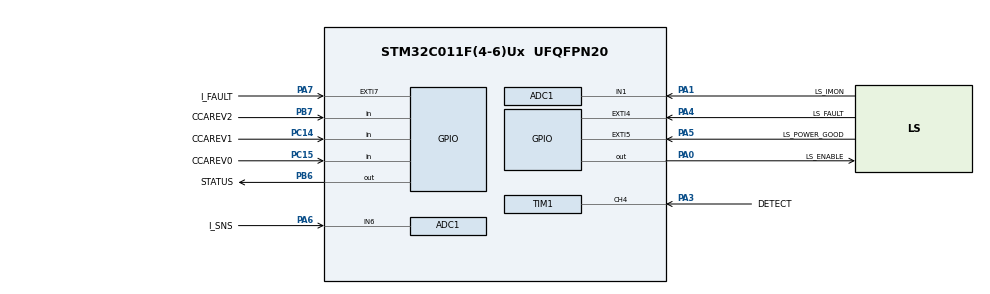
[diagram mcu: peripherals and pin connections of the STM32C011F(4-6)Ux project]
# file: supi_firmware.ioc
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ADC1.AWD2HighThreshold=3165
ADC1.AWD2ITMode=ENABLE
ADC1.AWDChannel-0\#ChannelRegularConversion=ADC_CHANNEL_6
ADC1.Channel-0\#ChannelRegularConversion=ADC_CHANNEL_6
ADC1.ContinuousConvMode=ENABLE
ADC1.DataAlign=ADC_DATAALIGN_RIGHT
ADC1.EnableAnalogWatchDog1=false
ADC1.EnableAnalogWatchDog2=true
ADC1.EnableAnalogWatchDog3=false
ADC1.MonitoredBy-0\#ChannelRegularConversion=ADC_ANALOGWATCHDOG_2
ADC1.NbrOfConversion=1
ADC1.NbrOfConversionFlag=1
ADC1.Overrun=ADC_OVR_DATA_OVERWRITTEN
ADC1.OversamplingMode=DISABLE
ADC1.Rank-0\#ChannelRegularConversion=1
ADC1.SamplingTime-0\#ChannelRegularConversion=ADC_SAMPLINGTIME_COMMON_1
ADC1.SamplingTimeCommon1=ADC_SAMPLETIME_1CYCLE_5
ADC1.SamplingTimeCommon2=ADC_SAMPLETIME_1CYCLE_5
ADC1.SelectedChannel=ADC_CHANNEL_1|ADC_CHANNEL_6
ADC1.WDG2ChannelR1=ADC_CHANNEL_6
ADC1.master=1
Mcu.Family=STM32C0
Mcu.Name=STM32C011F(4-6)Ux
Mcu.Package=UFQFPN20
NVIC.ADC1_IRQn=true\:0\:0\:false\:false\:true\:true\:true\:true
PA0.GPIO_Label=LS_ENABLE
PA0.Signal=GPIO_Output
PA1.GPIO_Label=LS_IMON
PA1.Mode=IN1
PA1.Signal=ADC1_IN1
PA13.Mode=Serial_Wire
PA13.Signal=DEBUG_SWDIO
PA14-BOOT0.Mode=Serial_Wire
PA14-BOOT0.Signal=DEBUG_SWCLK
PA3.GPIO_Label=DETECT
PA3.Signal=S_TIM1_CH4
PA4.GPIO_Label=LS_FAULT
PA4.GPIO_ModeDefaultEXTI=GPIO_MODE_IT_RISING
PA4.Signal=GPXTI4
PA5.GPIO_Label=LS_POWER_GOOD
PA5.Signal=GPXTI5
PA6.GPIO_Label=I_SNS
PA6.Mode=IN6
PA6.Signal=ADC1_IN6
PA7.GPIO_Label=I_FAULT
PA7.Signal=GPXTI7
PB6.GPIO_FM6=SYSCFG_FASTMODEPLUS_PB6
PB6.GPIO_Label=STATUS
PB6.GPIO_Speed=GPIO_SPEED_FREQ_VERY_HIGH
PB6.Signal=GPIO_Output
PB7.GPIO_Label=CCAREV2
PB7.GPIO_PuPd=GPIO_PULLDOWN
PB7.Signal=GPIO_Input
PC14-OSCX_IN\ (PC14).GPIO_Label=CCAREV1
PC14-OSCX_IN\ (PC14).GPIO_PuPd=GPIO_PULLDOWN
PC14-OSCX_IN\ (PC14).Signal=GPIO_Input
PC15-OSCX_OUT\ (PC15).GPIO_Label=CCAREV0
PC15-OSCX_OUT\ (PC15).GPIO_PuPd=GPIO_PULLDOWN
PC15-OSCX_OUT\ (PC15).Signal=GPIO_Input
ProjectManager.HeapSize=0x200
ProjectManager.StackSize=0x400
ProjectManager.TargetToolchain=MDK-ARM V5.32
RCC.ADCFreq_Value=48000000
RCC.AHBFreq_Value=48000000
RCC.CortexFreq_Value=48000000
RCC.EXTERNAL_CLOCK_VALUE=12288000
RCC.HCLKFreq_Value=48000000
RCC.HSE_VALUE=8000000
RCC.HSISYSCLKDivider=RCC_HSI_DIV1
RCC.HSI_VALUE=48000000
RCC.LSE_VALUE=32768
RCC.SYSCLKFreq_VALUE=48000000
SH.S_TIM1_CH4.0=TIM1_CH4,Input_Capture4_from_TI4
TIM1.Channel-Input_Capture4_from_TI4=TIM_CHANNEL_4
TIM1.ICFilter_CH4=3
TIM1.ICPolarity_CH4=TIM_INPUTCHANNELPOLARITY_FALLING
TIM1.Prescaler=48
TIM14.Channel=TIM_CHANNEL_1
TIM14.Prescaler=48
VP_TIM14_VS_ClockSourceINT.Mode=Enable_Timer
VP_TIM14_VS_OPM.Mode=OPM_bit
VP_TIM14_VS_no_output1.Mode=Output Compare1 No Output
VP_TIM1_VS_OPM.Mode=OPM_bit
board=custom

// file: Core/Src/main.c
/* USER CODE BEGIN Header */
/**
  ******************************************************************************
  * @file           : main.c
  * @brief          : Main program body
  ******************************************************************************
  * @attention
  *
  * Copyright (c) 2023 STMicroelectronics.
  * All rights reserved.
  *
  * This software is licensed under terms that can be found in the LICENSE file
  * in the root directory of this software component.
  * If no LICENSE file comes with this software, it is provided AS-IS.
  *
  ******************************************************************************
  */
/* USER CODE END Header */
#include "main.h"

/* USER CODE BEGIN Includes */
#include "supi.h"
/* USER CODE END Includes */

ADC_HandleTypeDef hadc1;

TIM_HandleTypeDef htim1;
TIM_HandleTypeDef htim14;

void SystemClock_Config(void);
static void MX_GPIO_Init(void);
static void MX_ADC1_Init(void);
static void MX_TIM1_Init(void);
static void MX_TIM14_Init(void);

int main(void)
{

  /* MCU Configuration--------------------------------------------------------*/

  /* Reset of all peripherals, Initializes the Flash interface and the Systick. */
  HAL_Init();

  /* Configure the system clock */
  SystemClock_Config();

  /* Initialize all configured peripherals */
  MX_GPIO_Init();
  MX_ADC1_Init();
  MX_TIM1_Init();
  MX_TIM14_Init();
  /* USER CODE BEGIN 2 */
    HAL_ADCEx_Calibration_Start(&hadc1);
    supi_initialize();
  /* USER CODE END 2 */

  /* Infinite loop */
  while (1)
  {

  }
}

void SystemClock_Config(void)
{
  RCC_OscInitTypeDef RCC_OscInitStruct = {0};
  RCC_ClkInitTypeDef RCC_ClkInitStruct = {0};

  /** Initializes the RCC Oscillators according to the specified parameters
  * in the RCC_OscInitTypeDef structure.
  */
  RCC_OscInitStruct.OscillatorType = RCC_OSCILLATORTYPE_HSI;
  RCC_OscInitStruct.HSIState = RCC_HSI_ON;
  RCC_OscInitStruct.HSIDiv = RCC_HSI_DIV1;
  RCC_OscInitStruct.HSICalibrationValue = RCC_HSICALIBRATION_DEFAULT;
  if (HAL_RCC_OscConfig(&RCC_OscInitStruct) != HAL_OK)
  {
    Error_Handler();
  }

  /** Initializes the CPU, AHB and APB buses clocks
  */
  RCC_ClkInitStruct.ClockType = RCC_CLOCKTYPE_HCLK|RCC_CLOCKTYPE_SYSCLK
                              |RCC_CLOCKTYPE_PCLK1;
  RCC_ClkInitStruct.SYSCLKSource = RCC_SYSCLKSOURCE_HSI;
  RCC_ClkInitStruct.SYSCLKDivider = RCC_SYSCLK_DIV1;
  RCC_ClkInitStruct.AHBCLKDivider = RCC_HCLK_DIV1;
  RCC_ClkInitStruct.APB1CLKDivider = RCC_APB1_DIV1;

  if (HAL_RCC_ClockConfig(&RCC_ClkInitStruct, FLASH_LATENCY_1) != HAL_OK)
  {
    Error_Handler();
  }
}

static void MX_ADC1_Init(void)
{

  ADC_ChannelConfTypeDef sConfig = {0};
  ADC_AnalogWDGConfTypeDef AnalogWDGConfig = {0};

  /** Configure the global features of the ADC (Clock, Resolution, Data Alignment and number of conversion)
  */
  hadc1.Instance = ADC1;
  hadc1.Init.ClockPrescaler = ADC_CLOCK_SYNC_PCLK_DIV2;
  hadc1.Init.Resolution = ADC_RESOLUTION_12B;
  hadc1.Init.DataAlign = ADC_DATAALIGN_RIGHT;
  hadc1.Init.ScanConvMode = ADC_SCAN_DISABLE;
  hadc1.Init.EOCSelection = ADC_EOC_SINGLE_CONV;
  hadc1.Init.LowPowerAutoWait = DISABLE;
  hadc1.Init.LowPowerAutoPowerOff = DISABLE;
  hadc1.Init.ContinuousConvMode = ENABLE;
  hadc1.Init.NbrOfConversion = 1;
  hadc1.Init.ExternalTrigConv = ADC_SOFTWARE_START;
  hadc1.Init.ExternalTrigConvEdge = ADC_EXTERNALTRIGCONVEDGE_NONE;
  hadc1.Init.DMAContinuousRequests = DISABLE;
  hadc1.Init.Overrun = ADC_OVR_DATA_OVERWRITTEN;
  hadc1.Init.SamplingTimeCommon1 = ADC_SAMPLETIME_1CYCLE_5;
  hadc1.Init.SamplingTimeCommon2 = ADC_SAMPLETIME_1CYCLE_5;
  hadc1.Init.OversamplingMode = DISABLE;
  hadc1.Init.TriggerFrequencyMode = ADC_TRIGGER_FREQ_HIGH;
  if (HAL_ADC_Init(&hadc1) != HAL_OK)
  {
    Error_Handler();
  }

  /** Configure Regular Channel
  */
  sConfig.Channel = ADC_CHANNEL_6;
  sConfig.Rank = ADC_REGULAR_RANK_1;
  sConfig.SamplingTime = ADC_SAMPLINGTIME_COMMON_1;
  if (HAL_ADC_ConfigChannel(&hadc1, &sConfig) != HAL_OK)
  {
    Error_Handler();
  }

  /** Configure the regular channel to be monitored by WatchDog 2 or 3
  */
  AnalogWDGConfig.WatchdogNumber = ADC_ANALOGWATCHDOG_2;
  AnalogWDGConfig.WatchdogMode = ADC_ANALOGWATCHDOG_SINGLE_REG;
  AnalogWDGConfig.Channel = ADC_CHANNEL_6;
  AnalogWDGConfig.ITMode = ENABLE;
  AnalogWDGConfig.HighThreshold = 3165;
  AnalogWDGConfig.LowThreshold = 0;
  if (HAL_ADC_AnalogWDGConfig(&hadc1, &AnalogWDGConfig) != HAL_OK)
  {
    Error_Handler();
  }
  /* USER CODE BEGIN ADC1_Init 2 */
  /* NOTE: High threshold for watchdog 2 is computed as follows:
   *   Current sensor quiescent output voltage: 1.65V
   *   V_ref = 3.3V (equivalent to 4095 counts on 12-bit ADC)
   *   Sensitivity: 0.09V/A
   *   10A threshold -> 0.9V offset from baseline, or 2.55V total
   *   2.55V/3.3V = 0.773
   *   0.773 * 4095 counts = 3164 counts
   *
   * Any ADC value below ~2048 would indicate a reverse current flow.
   * This is unlikely to happen in real use.  The low threshold is set to
   * zero so that this can be tested on a development board without
   * constantly triggering watchdog events.
   */
  /* USER CODE END ADC1_Init 2 */

}

static void MX_TIM1_Init(void)
{

  TIM_MasterConfigTypeDef sMasterConfig = {0};
  TIM_IC_InitTypeDef sConfigIC = {0};

  htim1.Instance = TIM1;
  htim1.Init.Prescaler = 48;
  htim1.Init.CounterMode = TIM_COUNTERMODE_UP;
  htim1.Init.Period = 65535;
  htim1.Init.ClockDivision = TIM_CLOCKDIVISION_DIV1;
  htim1.Init.RepetitionCounter = 0;
  htim1.Init.AutoReloadPreload = TIM_AUTORELOAD_PRELOAD_DISABLE;
  if (HAL_TIM_IC_Init(&htim1) != HAL_OK)
  {
    Error_Handler();
  }
  if (HAL_TIM_OnePulse_Init(&htim1, TIM_OPMODE_SINGLE) != HAL_OK)
  {
    Error_Handler();
  }
  sMasterConfig.MasterOutputTrigger = TIM_TRGO_RESET;
  sMasterConfig.MasterOutputTrigger2 = TIM_TRGO2_RESET;
  sMasterConfig.MasterSlaveMode = TIM_MASTERSLAVEMODE_DISABLE;
  if (HAL_TIMEx_MasterConfigSynchronization(&htim1, &sMasterConfig) != HAL_OK)
  {
    Error_Handler();
  }
  sConfigIC.ICPolarity = TIM_INPUTCHANNELPOLARITY_FALLING;
  sConfigIC.ICSelection = TIM_ICSELECTION_DIRECTTI;
  sConfigIC.ICPrescaler = TIM_ICPSC_DIV1;
  sConfigIC.ICFilter = 3;
  if (HAL_TIM_IC_ConfigChannel(&htim1, &sConfigIC, TIM_CHANNEL_4) != HAL_OK)
  {
    Error_Handler();
  }

}

static void MX_TIM14_Init(void)
{

  TIM_OC_InitTypeDef sConfigOC = {0};

  htim14.Instance = TIM14;
  htim14.Init.Prescaler = 48;
  htim14.Init.CounterMode = TIM_COUNTERMODE_UP;
  htim14.Init.Period = 65535;
  htim14.Init.ClockDivision = TIM_CLOCKDIVISION_DIV1;
  htim14.Init.AutoReloadPreload = TIM_AUTORELOAD_PRELOAD_DISABLE;
  if (HAL_TIM_Base_Init(&htim14) != HAL_OK)
  {
    Error_Handler();
  }
  if (HAL_TIM_OC_Init(&htim14) != HAL_OK)
  {
    Error_Handler();
  }
  if (HAL_TIM_OnePulse_Init(&htim14, TIM_OPMODE_SINGLE) != HAL_OK)
  {
    Error_Handler();
  }
  sConfigOC.OCMode = TIM_OCMODE_TIMING;
  sConfigOC.Pulse = 0;
  sConfigOC.OCPolarity = TIM_OCPOLARITY_HIGH;
  sConfigOC.OCFastMode = TIM_OCFAST_DISABLE;
  if (HAL_TIM_OC_ConfigChannel(&htim14, &sConfigOC, TIM_CHANNEL_1) != HAL_OK)
  {
    Error_Handler();
  }

}

static void MX_GPIO_Init(void)
{
  GPIO_InitTypeDef GPIO_InitStruct = {0};

  /* GPIO Ports Clock Enable */
  __HAL_RCC_GPIOC_CLK_ENABLE();
  __HAL_RCC_GPIOA_CLK_ENABLE();
  __HAL_RCC_GPIOB_CLK_ENABLE();

  /*Configure GPIO pin Output Level */
  HAL_GPIO_WritePin(LS_ENABLE_GPIO_Port, LS_ENABLE_Pin, GPIO_PIN_RESET);

  /*Configure GPIO pin Output Level */
  HAL_GPIO_WritePin(STATUS_GPIO_Port, STATUS_Pin, GPIO_PIN_RESET);

  /*Configure GPIO pins : CCAREV0_Pin CCAREV1_Pin */
  GPIO_InitStruct.Pin = CCAREV0_Pin|CCAREV1_Pin;
  GPIO_InitStruct.Mode = GPIO_MODE_INPUT;
  GPIO_InitStruct.Pull = GPIO_PULLDOWN;
  HAL_GPIO_Init(GPIOC, &GPIO_InitStruct);

  /*Configure GPIO pin : LS_ENABLE_Pin */
  GPIO_InitStruct.Pin = LS_ENABLE_Pin;
  GPIO_InitStruct.Mode = GPIO_MODE_OUTPUT_PP;
  GPIO_InitStruct.Pull = GPIO_NOPULL;
  GPIO_InitStruct.Speed = GPIO_SPEED_FREQ_LOW;
  HAL_GPIO_Init(LS_ENABLE_GPIO_Port, &GPIO_InitStruct);

  /*Configure GPIO pins : LS_FAULT_Pin LS_POWER_GOOD_Pin I_FAULT_Pin */
  GPIO_InitStruct.Pin = LS_FAULT_Pin|LS_POWER_GOOD_Pin|I_FAULT_Pin;
  GPIO_InitStruct.Mode = GPIO_MODE_IT_RISING;
  GPIO_InitStruct.Pull = GPIO_NOPULL;
  HAL_GPIO_Init(GPIOA, &GPIO_InitStruct);

  /*Configure GPIO pin : STATUS_Pin */
  GPIO_InitStruct.Pin = STATUS_Pin;
  GPIO_InitStruct.Mode = GPIO_MODE_OUTPUT_PP;
  GPIO_InitStruct.Pull = GPIO_NOPULL;
  GPIO_InitStruct.Speed = GPIO_SPEED_FREQ_VERY_HIGH;
  HAL_GPIO_Init(STATUS_GPIO_Port, &GPIO_InitStruct);

  /*Configure GPIO pin : CCAREV2_Pin */
  GPIO_InitStruct.Pin = CCAREV2_Pin;
  GPIO_InitStruct.Mode = GPIO_MODE_INPUT;
  GPIO_InitStruct.Pull = GPIO_PULLDOWN;
  HAL_GPIO_Init(CCAREV2_GPIO_Port, &GPIO_InitStruct);

  /**/
  __HAL_SYSCFG_FASTMODEPLUS_ENABLE(SYSCFG_FASTMODEPLUS_PB6);

}

void Error_Handler(void)
{
  __disable_irq();
  while (1)
  {
  }
}
